# STM32H745xx_CM7 register map
File version: 1.0
Registers are 32-bit, read-write, reset 0x0 unless marked. A register's access mark holds for its fields unless they carry their own. Offsets are from the block's base; [hi:lo] are bit positions; {n}, {i} and the like mark numbered series; 'fields as' and 'values as' point back to an identical list.

## DMAMUX1
Base 0x40020800
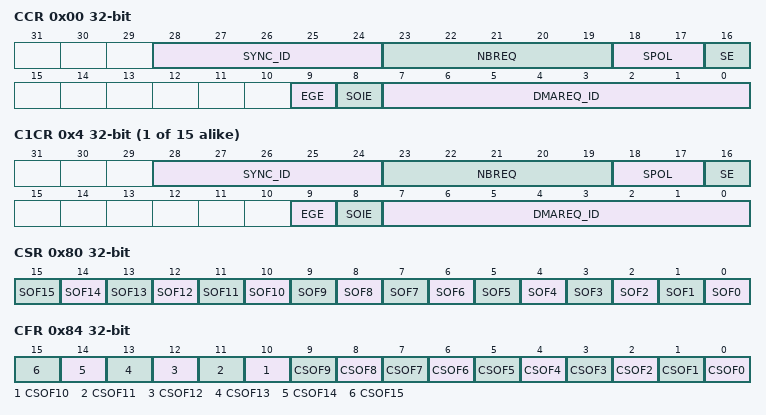
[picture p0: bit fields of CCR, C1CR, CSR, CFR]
0x00 CCR — DMA Multiplexer Channel x Control Register
  [28:24] SYNC_ID — Synchronization identification
  [23:19] NBREQ — Number of DMA requests minus 1 to forward
  [18:17] SPOL — Synchronization polarity
  [16] SE — Synchronization enable
  [9] EGE — Event generation enable
  [8] SOIE — Synchronization overrun interrupt enable
  [7:0] DMAREQ_ID — DMA request identification
{0x0+4i} C{i}CR (i=1..15) — DMA Multiplexer Channel x Control Register
  fields as CCR
0x80 CSR — DMA Channel Status Register
  [n] SOF{n} (n=0..15) — Channel {n} Synchronization overrun event flag
0x84 CFR — DMA Channel Clear Flag Register
  [n] CSOF{n} (n=0..15) — Channel {n} Clear synchronization overrun event flag
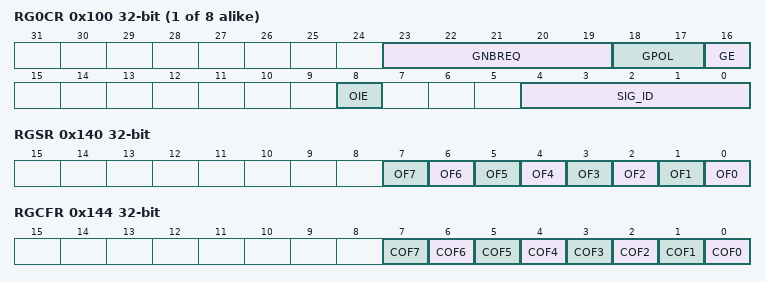
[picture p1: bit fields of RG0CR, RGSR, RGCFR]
{0x100+4i} RG{i}CR (i=0..7) — DMA Request Generator x Control Register
  [23:19] GNBREQ — Number of DMA requests to be generated
  [18:17] GPOL — DMA request generator trigger polarity
  [16] GE — DMA request generator enable
  [8] OIE — Trigger overrun interrupt enable
  [4:0] SIG_ID — Signal identification
0x140 RGSR — DMA Request Generator Status Register
  [n] OF{n} (n=0..7) — Request generator channel {n} Trigger overrun event flag
0x144 RGCFR — DMA Request Generator Clear Flag Register
  [n] COF{n} (n=0..7) — Request generator channel {n} Clear trigger overrun event flag

## DMAMUX2
Base 0x58025800
Registers as DMAMUX1, without C{n}CR (n=8..15).

## ART
Base 0x40024400
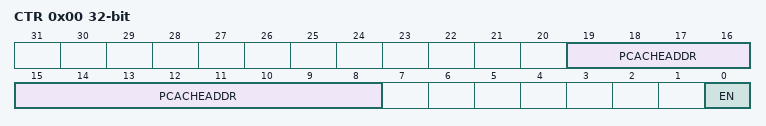
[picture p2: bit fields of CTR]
0x00 CTR — ART accelerator - control register
  [19:8] PCACHEADDR — Cacheable page index
  [0] EN — Cache enable

## DCMI
Base 0x48020000
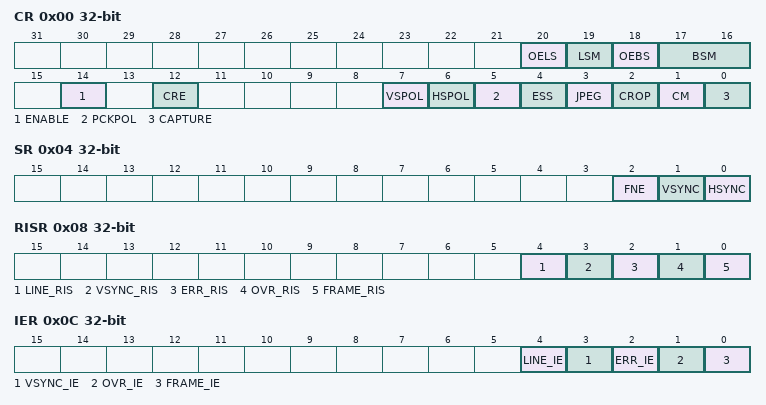
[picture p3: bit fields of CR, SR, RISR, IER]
0x00 CR — DCMI control register 1
  [20] OELS, [19] LSM, [18] OEBS, [17:16] BSM, [14] ENABLE, [12] CRE, [7] VSPOL, [6] HSPOL, [5] PCKPOL, [4] ESS, [3] JPEG, [2] CROP, [1] CM, [0] CAPTURE
0x04 SR — DCMI status register
  [2] FNE, [1] VSYNC, [0] HSYNC
0x08 RISR — DCMI raw interrupt status register
  [4] LINE_RIS, [3] VSYNC_RIS, [2] ERR_RIS, [1] OVR_RIS, [0] FRAME_RIS
0x0C IER — DCMI interrupt enable register
  [4] LINE_IE, [3] VSYNC_IE, [2] ERR_IE, [1] OVR_IE, [0] FRAME_IE
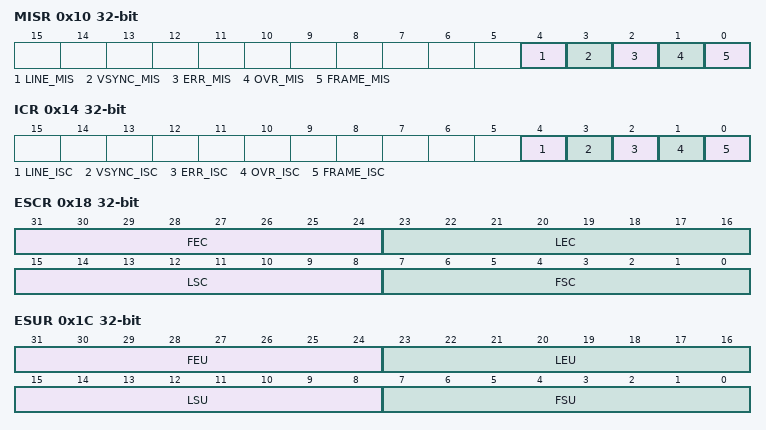
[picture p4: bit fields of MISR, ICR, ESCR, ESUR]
0x10 MISR — DCMI masked interrupt status register
  [4] LINE_MIS, [3] VSYNC_MIS, [2] ERR_MIS, [1] OVR_MIS, [0] FRAME_MIS
0x14 ICR — DCMI interrupt clear register
  [4] LINE_ISC, [3] VSYNC_ISC, [2] ERR_ISC, [1] OVR_ISC, [0] FRAME_ISC
0x18 ESCR — DCMI embedded synchronization code register
  [31:24] FEC, [23:16] LEC, [15:8] LSC, [7:0] FSC
0x1C ESUR — DCMI embedded synchronization unmask register
  [31:24] FEU, [23:16] LEU, [15:8] LSU, [7:0] FSU
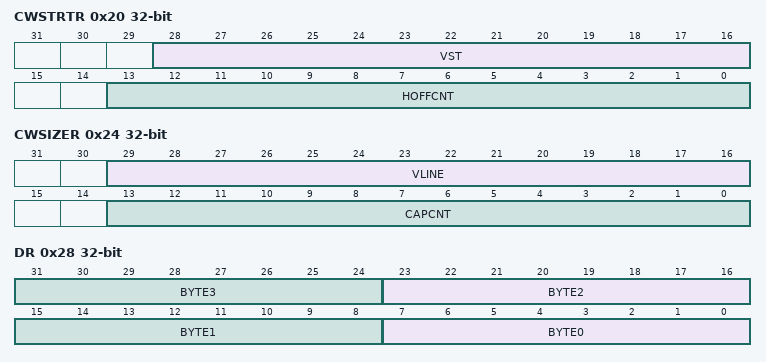
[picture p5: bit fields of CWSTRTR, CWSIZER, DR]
0x20 CWSTRTR — DCMI crop window start
  [28:16] VST, [13:0] HOFFCNT
0x24 CWSIZER — DCMI crop window size
  [29:16] VLINE, [13:0] CAPCNT
0x28 DR — DCMI data register
  [8n+7:8n] BYTE{n} (n=0..3)

## RNG
Base 0x48021800
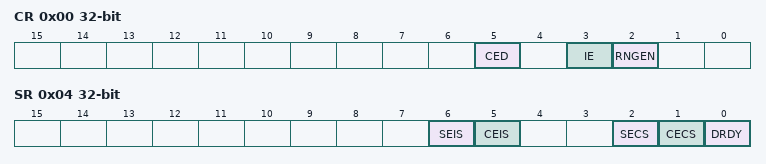
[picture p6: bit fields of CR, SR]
0x00 CR — RNG control register
  [5] CED, [3] IE, [2] RNGEN
0x04 SR — RNG status register
  [6] SEIS, [5] CEIS, [2] SECS, [1] CECS, [0] DRDY
0x08 DR — RNG data register

## DLYB_SDMMC2 — Delay Block DLYB
Base 0x48022800
Same registers: DLYB_QUADSPI 0x52006000, DLYB_SDMMC1 0x52008000
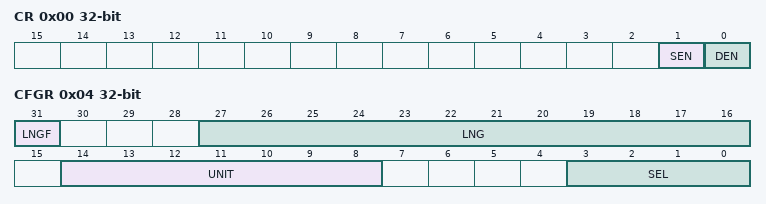
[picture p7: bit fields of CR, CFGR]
0x00 CR — DELAY BLOCK control register
  [1] SEN — Sampler length enable
  [0] DEN — Delay Block enable
0x04 CFGR — DELAY BLOCK configuration register
  [31] LNGF — Length valid flag
  [27:16] LNG — Delay line length value[11:0]
  [14:8] UNIT — Delay Defines the delay of a Unit delay cell[6:0]
  [3:0] SEL — Select the phase for the Output clock[3:0]

## RAMECC2
Base 0x48023000
Same registers: RAMECC1 0x52009000
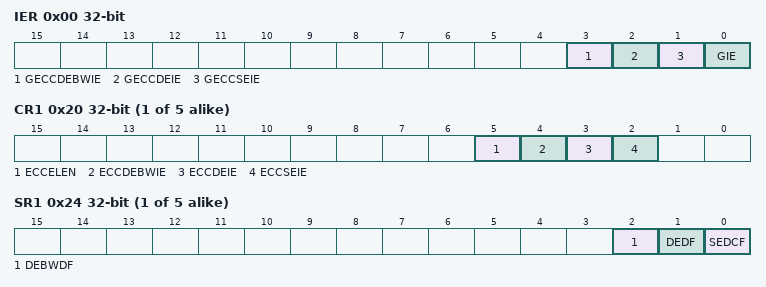
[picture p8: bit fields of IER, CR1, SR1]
0x00 IER — RAMECC interrupt enable register
  [3] GECCDEBWIE — Global ECC double error on byte write (BW) interrupt enable
  [2] GECCDEIE — Global ECC double error interrupt enable
  [1] GECCSEIE — Global ECC single error interrupt enable
  [0] GIE — Global interrupt enable
{0x0+0x20*i} CR{i} (i=1..5) — RAMECC monitor configuration register
  [5] ECCELEN — ECC error latching enable
  [4] ECCDEBWIE — ECC double error on byte write (BW) interrupt enable
  [3] ECCDEIE — ECC double error interrupt enable
  [2] ECCSEIE — ECC single error interrupt enable
{0x4+0x20*i} SR{i} (i=1..5) — RAMECC monitor status register
  [2] DEBWDF — ECC double error on byte write (BW) detected flag
  [1] DEDF — ECC double error detected flag
  [0] SEDCF — ECC single error detected and corrected flag
{0x8+0x20*i} FAR{i} (i=1..5) — RAMECC monitor failing address register
  [31:0] FADD — ECC error failing address
{0xC+0x20*i} FDRL{i} (i=1..5) — RAMECC monitor failing data low register
{0x10+0x20*i} FDRH{i} (i=1..5) — RAMECC monitor failing data high register
{0x14+0x20*i} FECR{i} (i=1..5) — RAMECC monitor failing ECC error code register
  [31:0] FEC — Failing error code

## RAMECC3
Base 0x58027000
Registers as RAMECC2, without CR{n} (n=3..5), SR{n} (n=3..5), FAR{n} (n=3..5), FDRL{n} (n=3..5), FDRH{n} (n=3..5), FECR{n} (n=3..5).
